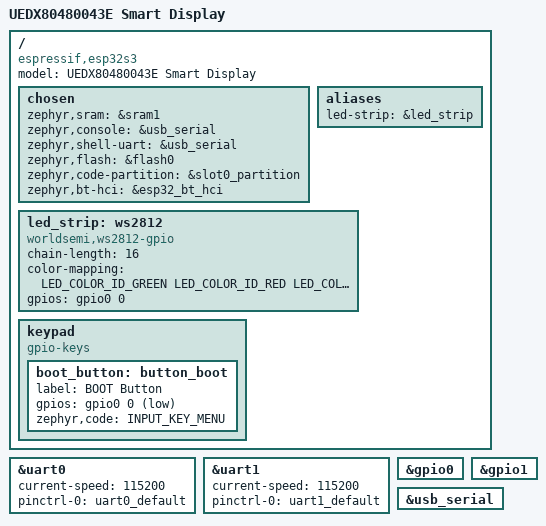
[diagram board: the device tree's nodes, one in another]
/dts-v1/;
#include <espressif/esp32s3/esp32s3_wroom_n16r8.dtsi>
#include "uedx80480043e-pinctrl.dtsi"
#include <zephyr/dt-bindings/input/input-event-codes.h>
#include <espressif/partitions_0x0_amp.dtsi>
#include <zephyr/dt-bindings/gpio/gpio.h>
#include <zephyr/dt-bindings/led/led.h>


/ {
    model = "UEDX80480043E Smart Display";
    compatible = "espressif,esp32s3";

    chosen {
        zephyr,sram = &sram1;
		/* console can be UART or USB CDC */
		/* zephyr,console = &uart0; */
		/* zephyr,shell-uart = &uart0; */
		zephyr,console = &usb_serial;
		zephyr,shell-uart = &usb_serial;
		zephyr,flash = &flash0;
		zephyr,code-partition = &slot0_partition;
		zephyr,bt-hci = &esp32_bt_hci;
    };

    aliases {
		led-strip = &led_strip;
	};

    led_strip: ws2812 {
		compatible = "worldsemi,ws2812-gpio";

		chain-length = <16>; /* arbitrary */
		color-mapping = <LED_COLOR_ID_GREEN
				 LED_COLOR_ID_RED
				 LED_COLOR_ID_BLUE>;
		/*
		 * Arduino D11 / P0.25, which was chosen to match the pin
		 * used in nrf52dk_nrf52832.overlay.
		 */
		gpios = <&gpio0 0 0>;
	};

	keypad {
        compatible = "gpio-keys";
        status = "okay";
        boot_button: button_boot {
            label = "BOOT Button";
            gpios = <&gpio0 0 (GPIO_PULL_UP | GPIO_ACTIVE_LOW)>;
            zephyr,code = <INPUT_KEY_MENU>;
        };
    };
};

&uart0 {
	status = "okay";
	current-speed = <115200>;
	pinctrl-0 = <&uart0_default>;
	pinctrl-names = "default";
};

&uart1 {
	status = "okay";
	current-speed = <115200>;
	pinctrl-0 = <&uart1_default>;
	pinctrl-names = "default";
};

&gpio0 {
	status = "okay";
};

&gpio1 {
	status = "okay";
};

&usb_serial {
	status = "okay";
};
